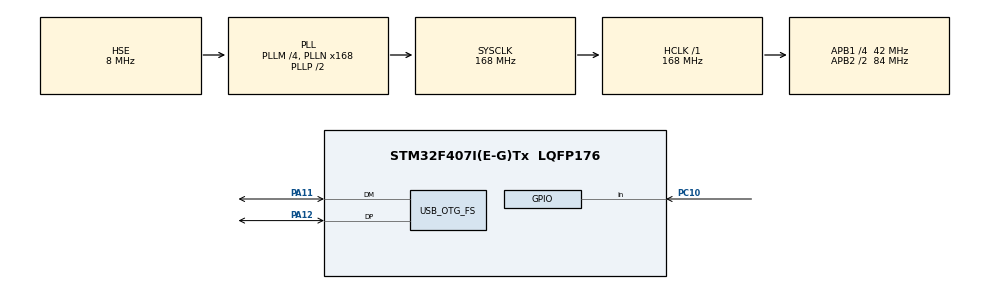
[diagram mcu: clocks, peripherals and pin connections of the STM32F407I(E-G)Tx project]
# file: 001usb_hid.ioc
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Mcu.Family=STM32F4
USB_DEVICE.CLASS_NAME_FS=HID
PH0-OSC_IN.Signal=RCC_OSC_IN
RCC.CortexFreq_Value=168000000
USB_DEVICE.VirtualModeFS=Hid_FS
PC10.Signal=GPIO_Input
PA11.Mode=Device_Only
RCC.APB1CLKDivider=RCC_HCLK_DIV4
RCC.SYSCLKSource=RCC_SYSCLKSOURCE_PLLCLK
ProjectManager.StackSize=0x400
PA12.Signal=USB_OTG_FS_DP
ProjectManager.TargetToolchain=STM32CubeIDE
RCC.HCLKFreq_Value=168000000
RCC.APB2TimFreq_Value=168000000
RCC.LSE_VALUE=32768
RCC.AHBFreq_Value=168000000
PH0-OSC_IN.Mode=HSE-External-Oscillator
RCC.HSE_VALUE=8000000
board=custom
RCC.VCOOutputFreq_Value=336000000
VP_USB_DEVICE_VS_USB_DEVICE_HID_FS.Mode=HID_FS
RCC.APB2Freq_Value=84000000
PH1-OSC_OUT.Signal=RCC_OSC_OUT
Mcu.Name=STM32F407I(E-G)Tx
RCC.48MHZClocksFreq_Value=48000000
PH1-OSC_OUT.Mode=HSE-External-Oscillator
RCC.SYSCLKFreq_VALUE=168000000
Mcu.Package=LQFP176
PA12.Mode=Device_Only
NVIC.OTG_FS_IRQn=true\:0\:0\:false\:false\:true\:false\:true
PA11.Signal=USB_OTG_FS_DM
USB_OTG_FS.VirtualMode=Device_Only
ProjectManager.HeapSize=0x200
RCC.HSI_VALUE=16000000
RCC.PLLQ=7
NVIC.PriorityGroup=NVIC_PRIORITYGROUP_4
RCC.APB2CLKDivider=RCC_HCLK_DIV2
RCC.PLLM=4
RCC.PLLN=168
RCC.APB1TimFreq_Value=84000000
RCC.APB1Freq_Value=42000000
USB_DEVICE.VirtualMode-HID_FS=Hid

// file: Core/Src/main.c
/* USER CODE BEGIN Header */
/**
  ******************************************************************************
  * @file           : main.c
  * @brief          : Main program body
  ******************************************************************************
  * @attention
  *
  * <h2><center>&copy; Copyright (c) 2021 STMicroelectronics.
  * All rights reserved.</center></h2>
  *
  * This software component is licensed by ST under BSD 3-Clause license,
  * the "License"; You may not use this file except in compliance with the
  * License. You may obtain a copy of the License at:
  *                        opensource.org/licenses/BSD-3-Clause
  *
  ******************************************************************************
  */
/* USER CODE END Header */
#include "main.h"
#include "usb_device.h"

/* USER CODE BEGIN Includes */
#include "usbd_hid.h"
/* USER CODE END Includes */

/* USER CODE BEGIN PV */
uint8_t buffer[4];
extern USBD_HandleTypeDef hUsbDeviceFS;
/* USER CODE END PV */

void SystemClock_Config(void);
static void MX_GPIO_Init(void);

int main(void)
{

  /* MCU Configuration--------------------------------------------------------*/

  /* Reset of all peripherals, Initializes the Flash interface and the Systick. */
  HAL_Init();

  /* Configure the system clock */
  SystemClock_Config();

  /* Initialize all configured peripherals */
  MX_GPIO_Init();
  MX_USB_DEVICE_Init();
  /* USER CODE BEGIN 2 */
  buffer[1] = 100;
  /* USER CODE END 2 */

  /* Infinite loop */
  while (1)
  {

    /* USER CODE BEGIN 3 */
	if ( HAL_GPIO_ReadPin(GPIOC, GPIO_PIN_10) == GPIO_PIN_SET ) {
		USBD_HID_SendReport(&hUsbDeviceFS, buffer, 4);
		HAL_Delay(100);
	}
  }
  /* USER CODE END 3 */
}

void SystemClock_Config(void)
{
  RCC_OscInitTypeDef RCC_OscInitStruct = {0};
  RCC_ClkInitTypeDef RCC_ClkInitStruct = {0};

  /** Configure the main internal regulator output voltage
  */
  __HAL_RCC_PWR_CLK_ENABLE();
  __HAL_PWR_VOLTAGESCALING_CONFIG(PWR_REGULATOR_VOLTAGE_SCALE1);
  /** Initializes the RCC Oscillators according to the specified parameters
  * in the RCC_OscInitTypeDef structure.
  */
  RCC_OscInitStruct.OscillatorType = RCC_OSCILLATORTYPE_HSE;
  RCC_OscInitStruct.HSEState = RCC_HSE_ON;
  RCC_OscInitStruct.PLL.PLLState = RCC_PLL_ON;
  RCC_OscInitStruct.PLL.PLLSource = RCC_PLLSOURCE_HSE;
  RCC_OscInitStruct.PLL.PLLM = 4;
  RCC_OscInitStruct.PLL.PLLN = 168;
  RCC_OscInitStruct.PLL.PLLP = RCC_PLLP_DIV2;
  RCC_OscInitStruct.PLL.PLLQ = 7;
  if (HAL_RCC_OscConfig(&RCC_OscInitStruct) != HAL_OK)
  {
    Error_Handler();
  }
  /** Initializes the CPU, AHB and APB buses clocks
  */
  RCC_ClkInitStruct.ClockType = RCC_CLOCKTYPE_HCLK|RCC_CLOCKTYPE_SYSCLK
                              |RCC_CLOCKTYPE_PCLK1|RCC_CLOCKTYPE_PCLK2;
  RCC_ClkInitStruct.SYSCLKSource = RCC_SYSCLKSOURCE_PLLCLK;
  RCC_ClkInitStruct.AHBCLKDivider = RCC_SYSCLK_DIV1;
  RCC_ClkInitStruct.APB1CLKDivider = RCC_HCLK_DIV4;
  RCC_ClkInitStruct.APB2CLKDivider = RCC_HCLK_DIV2;

  if (HAL_RCC_ClockConfig(&RCC_ClkInitStruct, FLASH_LATENCY_5) != HAL_OK)
  {
    Error_Handler();
  }
}

static void MX_GPIO_Init(void)
{
  GPIO_InitTypeDef GPIO_InitStruct = {0};

  /* GPIO Ports Clock Enable */
  __HAL_RCC_GPIOH_CLK_ENABLE();
  __HAL_RCC_GPIOA_CLK_ENABLE();
  __HAL_RCC_GPIOC_CLK_ENABLE();

  /*Configure GPIO pin : PC10 */
  GPIO_InitStruct.Pin = GPIO_PIN_10;
  GPIO_InitStruct.Mode = GPIO_MODE_INPUT;
  GPIO_InitStruct.Pull = GPIO_NOPULL;
  HAL_GPIO_Init(GPIOC, &GPIO_InitStruct);

}

void Error_Handler(void)
{
  __disable_irq();
  while (1)
  {
  }
}

/************************ (C) COPYRIGHT STMicroelectronics *****END OF FILE****/
